AUTOSAR XML (schema 4-0-3)
package /ComponentTypes
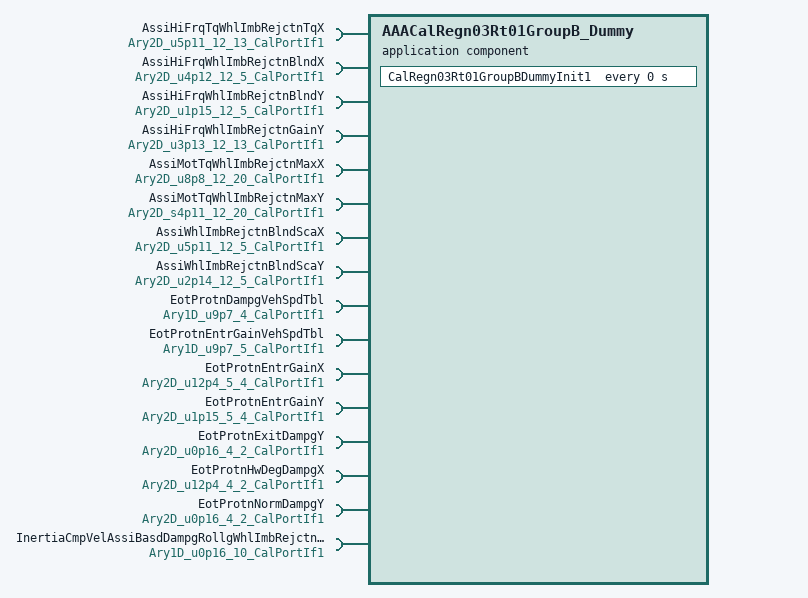
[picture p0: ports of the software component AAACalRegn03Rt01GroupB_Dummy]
  application sw component type AAACalRegn03Rt01GroupB_Dummy
    16 x require port:
      AssiHiFrqTqWhlImbRejctnTqX: parameter-require-com-spec{init-value=12 x [0, 512, 1024, 1536, 2048, 2560, 3072, 4096, 8192, 12288, 15360, 15872, 16384], parameter=Ary2D}, required-interface=Ary2D_u5p11_12_13_CalPortIf1
      AssiHiFrqWhlImbRejctnBlndX: parameter-require-com-spec{init-value=12 x [0, 1024, 2048, 3072, 4506], parameter=Ary2D}, required-interface=Ary2D_u4p12_12_5_CalPortIf1
      AssiHiFrqWhlImbRejctnBlndY: parameter-require-com-spec{init-value=12 x 5 x 0, parameter=Ary2D}, required-interface=Ary2D_u1p15_12_5_CalPortIf1
      AssiHiFrqWhlImbRejctnGainY: parameter-require-com-spec{init-value=12 x [2048, 1638, 1065, 655, 328, 82, 0, 0, 0, 0, 0, 0, 0], parameter=Ary2D}, required-interface=Ary2D_u3p13_12_13_CalPortIf1
      AssiMotTqWhlImbRejctnMaxX: parameter-require-com-spec{init-value=[[0, 26, 53, 63, 74, 86, 98, 110, 123, 134, 146, 159, 170, 182, 194, 205, 256, 372, 1220, 2560], [0, 26, 78, 101, 123, 148, 171, 196, 220, 243, 267, 290, 315, 339, 362, 435, 563, 719, 1624, 2560], [0, 51, 80, 113, 145, 176, 205, 238, 266, 297, 330, 360, 391, 422, 452, 538, 717, 916, 2216, 2560], [0, 51, 80, 110, 146, 173, 205, 237, 266, 299, 330, 360, 392, 423, 452, 484, 640, 917, 947, 2560], [0, 51, 80, 111, 143, 177, 207, 238, 267, 300, 330, 359, 392, 422, 453, 483, 640, 819, 947, 2560], [0, 51, 79, 111, 139, 174, 206, 236, 267, 300, 334, 366, 396, 428, 460, 494, 640, 819, 972, 2560], [0, 51, 80, 106, 142, 175, 205, 239, 270, 300, 332, 366, 398, 429, 462, 494, 640, 819, 972, 2560], [0, 51, 100, 130, 163, 194, 229, 261, 291, 324, 355, 388, 420, 451, 483, 515, 640, 819, 998, 2560], [0, 51, 100, 130, 164, 196, 232, 260, 297, 327, 360, 396, 430, 462, 493, 527, 666, 819, 1024, 2560], [0, 51, 100, 130, 164, 196, 232, 260, 297, 327, 360, 396, 430, 462, 493, 527, 666, 819, 1024, 2560], [0, 51, 100, 130, 164, 196, 232, 260, 297, 327, 360, 396, 430, 462, 493, 527, 666, 819, 1024, 2560], [0, 51, 100, 130, 164, 196, 232, 260, 297, 327, 360, 396, 430, 462, 493, 527, 666, 819, 1024, 2560]], parameter=Ary2D}, required-interface=Ary2D_u8p8_12_20_CalPortIf1
      AssiMotTqWhlImbRejctnMaxY: parameter-require-com-spec{init-value=[[0, 0, 48, 72, 104, 144, 192, 248, 312, 376, 448, 536, 616, 712, 816, 920, 1536, 3128, 17904, 17904], [0, 0, 64, 104, 152, 216, 288, 376, 472, 576, 696, 824, 968, 1120, 1280, 1761, 3072, 5120, 17904, 17904], [0, 0, 32, 80, 136, 200, 272, 360, 448, 552, 672, 792, 928, 1072, 1224, 1741, 3031, 4728, 17904, 17904], [0, 0, 32, 72, 128, 176, 240, 312, 384, 472, 560, 656, 760, 872, 984, 1112, 2048, 3568, 3792, 15632], [0, 0, 32, 72, 120, 176, 232, 296, 360, 440, 520, 600, 696, 792, 896, 1000, 1741, 2642, 3320, 13472], [0, 0, 32, 72, 112, 168, 224, 280, 344, 416, 496, 576, 656, 744, 840, 944, 1536, 2314, 3024, 11632], [0, 0, 32, 64, 112, 160, 208, 264, 320, 376, 440, 512, 584, 656, 736, 816, 1311, 1925, 2456, 9120], [0, 0, 48, 80, 120, 160, 208, 256, 304, 360, 416, 480, 544, 608, 680, 752, 1126, 1720, 2264, 8272], [0, 0, 48, 80, 120, 160, 208, 248, 304, 352, 408, 472, 536, 600, 664, 736, 1024, 1536, 2160, 7528], [0, 0, 48, 80, 120, 160, 208, 248, 304, 352, 408, 472, 536, 600, 664, 736, 1024, 1536, 2160, 7528], [0, 0, 48, 80, 120, 160, 208, 248, 304, 352, 408, 472, 536, 600, 664, 736, 1024, 1536, 2160, 7528], [0, 0, 48, 80, 120, 160, 208, 248, 304, 352, 408, 472, 536, 600, 664, 736, 1024, 1536, 2160, 7528]], parameter=Ary2D}, required-interface=Ary2D_s4p11_12_20_CalPortIf1
      AssiWhlImbRejctnBlndScaX: parameter-require-com-spec{init-value=12 x [0, 512, 1024, 1536, 2253], parameter=Ary2D}, required-interface=Ary2D_u5p11_12_5_CalPortIf1
      AssiWhlImbRejctnBlndScaY: parameter-require-com-spec{init-value=12 x 5 x 0, parameter=Ary2D}, required-interface=Ary2D_u2p14_12_5_CalPortIf1
      EotProtnDampgVehSpdTbl: parameter-require-com-spec{init-value=[0, 640, 1280, 2560], parameter=Ary1D}, required-interface=Ary1D_u9p7_4_CalPortIf1
      EotProtnEntrGainVehSpdTbl: parameter-require-com-spec{init-value=[0, 640, 1280, 1920, 2560], parameter=Ary1D}, required-interface=Ary1D_u9p7_5_CalPortIf1
      EotProtnEntrGainX: parameter-require-com-spec{init-value=5 x [0, 480, 960, 1440], parameter=Ary2D}, required-interface=Ary2D_u12p4_5_4_CalPortIf1
      EotProtnEntrGainY: parameter-require-com-spec{init-value=5 x [0, 10813, 21627, 32768], parameter=Ary2D}, required-interface=Ary2D_u1p15_5_4_CalPortIf1
      EotProtnExitDampgY: parameter-require-com-spec{init-value=[[0, 262], [0, 262], [0, 262], [0, 262]], parameter=Ary2D}, required-interface=Ary2D_u0p16_4_2_CalPortIf1
      EotProtnHwDegDampgX: parameter-require-com-spec{init-value=[[1920, 0], [1920, 0], [1920, 0], [1920, 0]], parameter=Ary2D}, required-interface=Ary2D_u12p4_4_2_CalPortIf1
      EotProtnNormDampgY: parameter-require-com-spec{init-value=[[0, 262], [0, 262], [0, 262], [0, 262]], parameter=Ary2D}, required-interface=Ary2D_u0p16_4_2_CalPortIf1
      InertiaCmpVelAssiBasdDampgRollgWhlImbRejctnOnY: parameter-require-com-spec{init-value=10 x 0, parameter=Ary1D}, required-interface=Ary1D_u0p16_10_CalPortIf1
    behavior AAACalRegn03Rt01GroupB_Dummy_InternalBehavior: supports-multiple-instantiation=true
      timing event AAACalRegn03Rt01GroupB_Dummy_InitEvent: start-on-event=CalRegn03Rt01GroupBDummyInit1, period=0
      runnable CalRegn03Rt01GroupBDummyInit1
  swc implementation AAACalRegn03Rt00GroupB_Dummy_Implementation: behavior=AAACalRegn03Rt01GroupB_Dummy_InternalBehavior
    code-descriptors:
      code Default: artifact-descriptors=autosar-engineering-object={short-label=Default, category=SWSRC}
